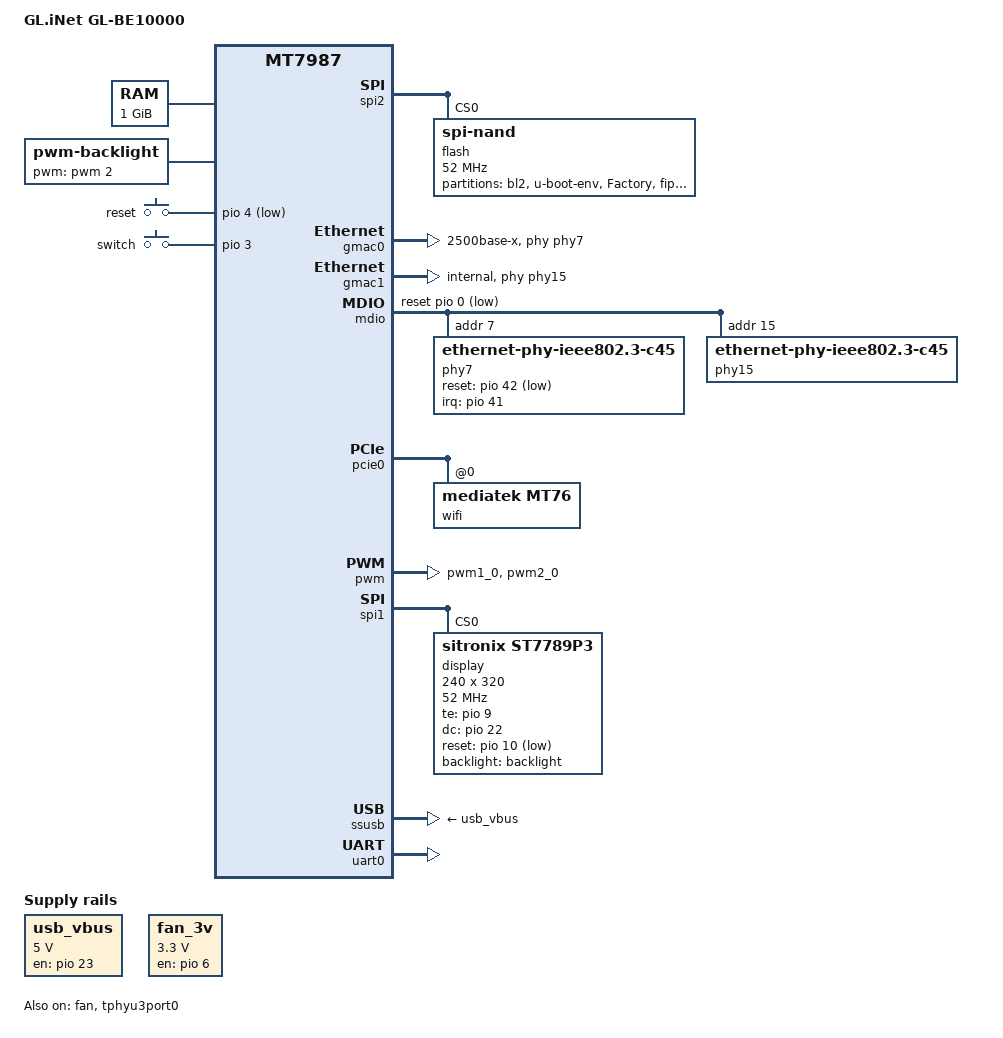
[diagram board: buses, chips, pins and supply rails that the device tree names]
// SPDX-License-Identifier: GPL-2.0-or-later OR MIT
/dts-v1/;
#include "mt7987a.dtsi"
#include <dt-bindings/input/input.h>

/ {
	model = "GL.iNet GL-BE10000";
	compatible = "glinet,gl-be10000", "mediatek,mt7987a", "mediatek,mt7987";

	memory@40000000 {
		device_type = "memory";
		reg = <0 0x40000000 0 0x40000000>;
	};

	aliases {
		serial0 = &uart0;
		label-mac-device = &gmac0;
	};

	backlight: backlight {
		compatible = "pwm-backlight";
		pwms = <&pwm 2 50000>;
		brightness-levels = <0    1    1    1    2    2    3    4    5    6    7
			  8    9   10   12   13   15   16   18   20   22
			 24   26   29   31   34   37   40   43   46   50
			 53   57   61   65   69   74   78   83   88   93
			 98  103  109  114  120  126  132  138  145  151
			158  165  172  179  187  194  202  210  218  226
			235  243  252  261  270  279  289  298  308  318
			328  338  349  359  370  381  392  403  415  426
			438  450  462  474  487  499  512  525  538  551
			565  578  592  606  620  634  649  663  678  693
			708  723  738  754  770  785  801  818  834  850
			867  884  901  918  935  952  970  988 1006 1023>;
		default-brightness-level = <95>;
	};

	chosen {
		bootargs = "console=ttyS0,115200n1 \
			    earlycon=uart8250,mmio32,0x11000000 \
			    pci=pcie_bus_perf \
			    fbcon=logo-count:1 vt.global_cursor_default=0";
		stdout-path = "serial0:115200n8";
	};

	gpio-keys {
		compatible = "gpio-keys";

		reset {
			label = "reset";
			linux,code = <KEY_RESTART>;
			gpios = <&pio 4 GPIO_ACTIVE_LOW>;
			debounce-interval = <10>;
		};

		switch {
			label = "switch";
			linux,code = <BTN_0>;
			gpios = <&pio 3 GPIO_ACTIVE_HIGH>;
			debounce-interval = <10>;
		};
	};

	usb_vbus: regulator-usb-vbus {
		compatible = "regulator-fixed";
		enable-active-high;
		gpios = <&pio 23 GPIO_ACTIVE_HIGH>;
		regulator-name = "usb_vbus";
		regulator-boot-on;
		regulator-min-microvolt = <5000000>;
		regulator-max-microvolt = <5000000>;
	};

	fan_3v: regulator-fan-3p3v {
		compatible = "regulator-fixed";
		enable-active-high;
		gpios = <&pio 6 GPIO_ACTIVE_HIGH>;
		regulator-name = "fan";
		regulator-min-microvolt = <3300000>;
		regulator-max-microvolt = <3300000>;
	};
};

&fan {
	fan-supply = <&fan_3v>;
	interrupt-parent = <&pio>;
	interrupts = <5 IRQ_TYPE_EDGE_RISING>;
	pwms = <&pwm 1 50000 0>;
	status = "okay";
};

&spi2 {
	pinctrl-names = "default";
	pinctrl-0 = <&spi2_flash_pins>;
	status = "okay";

	flash@0 {
		compatible = "spi-nand";
		reg = <0>;
		spi-max-frequency = <52000000>;
		spi-rx-bus-width = <4>;
		spi-tx-bus-width = <4>;
		mediatek,nmbm;
		mediatek,bmt-max-ratio = <1>;
		mediatek,bmt-max-reserved-blocks = <64>;

		partitions {
			compatible = "fixed-partitions";
			#address-cells = <1>;
			#size-cells = <1>;

			partition@0 {
				label = "bl2";
				reg = <0x00000 0x0100000>;
				read-only;
			};

			partition@100000 {
				label = "u-boot-env";
				reg = <0x0100000 0x0080000>;
			};

			factory: partition@180000 {
				label = "Factory";
				reg = <0x180000 0x0400000>;

				nvmem-layout {
					compatible = "fixed-layout";
					#address-cells = <1>;
					#size-cells = <1>;

					eeprom_factory_0: eeprom@0 {
						reg = <0x0 0x1e00>;
					};

					macaddr_factory_4: macaddr@4000 {
						reg = <0x4000 0x6>;
						compatible = "mac-base";
						#nvmem-cell-cells = <1>;
					};
				};
			};

			partition@580000 {
				label = "fip";
				reg = <0x580000 0x0300000>;
			};

			partition@880000 {
				label = "log";
				reg = <0x880000 0x0040000>;
			};

			partition@8c0000 {
				label = "CFG";
				reg = <0x8c0000 0x0040000>;
			};

			partition@900000 {
				label = "ubi";
				reg = <0x900000 0x1d700000>;
				compatible = "linux,ubi";
			};
		};
	};
};

&gmac0 {
	phy-mode = "2500base-x";
	phy-handle = <&phy7>;
	status = "okay";
	nvmem-cells = <&macaddr_factory_4 0>;
	nvmem-cell-names = "mac-address";
};

&gmac1 {
	phy-mode = "internal";
	phy-handle = <&phy15>;
	status = "okay";
	nvmem-cells = <&macaddr_factory_4 1>;
	nvmem-cell-names = "mac-address";
};

&mdio {
	reset-gpios = <&pio 0 GPIO_ACTIVE_LOW>;
	reset-delay-us = <10000>;

	phy7: phy@7 {
		compatible = "ethernet-phy-ieee802.3-c45";
		reg = <7>;
		reset-assert-us = <100000>;
		reset-deassert-us = <100000>;
		reset-gpios = <&pio 42 GPIO_ACTIVE_LOW>;
		interrupt-parent = <&pio>;
		interrupts = <41 IRQ_TYPE_LEVEL_LOW>;
	};

	phy15: phy@f {
		compatible = "ethernet-phy-ieee802.3-c45";
		reg = <15>;
		pinctrl-names = "i2p5gbe-led";
		pinctrl-0 = <&i2p5gbe_led0_pins>;
	};
};

&pcie0 {
	pinctrl-names = "default";
	pinctrl-0 = <&pcie0_pins>;
	status = "okay";

	pcie@0,0 {
		reg = <0x0000 0 0 0 0>;
		#address-cells = <3>;
		#size-cells = <2>;

		wifi@0,0 {
			compatible = "mediatek,mt76";
			reg = <0x0000 0 0 0 0>;

			nvmem-cells = <&eeprom_factory_0>;
			nvmem-cell-names = "eeprom";

			#address-cells = <1>;
			#size-cells = <0>;

			ieee80211-freq-limit = <2400000 2500000>,
					       <5170000 5835000>,
					       <5945000 7125000>;

			band@0 {
				reg = <0>;
				nvmem-cells = <&macaddr_factory_4 2>;
				nvmem-cell-names = "mac-address";
			};

			band@1 {
				reg = <1>;
				nvmem-cells = <&macaddr_factory_4 3>;
				nvmem-cell-names = "mac-address";
			};

			band@2 {
				reg = <2>;
				nvmem-cells = <&macaddr_factory_4 4>;
				nvmem-cell-names = "mac-address";
			};
		};
	};
};

&pio {
	pwm1_pins: pwm1-pins {
		mux {
			function = "pwm";
			groups = "pwm1_0";
		};
	};

	pwm2_pins: pwm2-pins {
		mux {
			function = "pwm";
			groups = "pwm2_0";
		};
	};
};

&pwm {
	pinctrl-names = "default";
	pinctrl-0 = <&pwm1_pins &pwm2_pins>;
	status = "okay";
};

&spi1 {
	pinctrl-names = "default";
	pinctrl-0 = <&spic_pins>;
	cs_setup_time = <2>;
	status = "okay";

	display@0 {
		compatible = "sitronix,st7789p3";
		reg = <0>;
		backlight = <&backlight>;
		buswidth = <8>;
		width = <240>;
		height = <320>;
		rotate = <0>;
		fps = <40>;
		te-gpios = <&pio 9 GPIO_ACTIVE_HIGH>;
		dc-gpios = <&pio 22 GPIO_ACTIVE_HIGH>;
		reset-gpios = <&pio 10 GPIO_ACTIVE_LOW>;
		spi-max-frequency = <52000000>;
	};
};

&spic_pins {
	mux {
		function = "spi";
		groups = "spi1_1";
	};
};

&ssusb {
	vbus-supply = <&usb_vbus>;
	status = "okay";
};

&tphyu3port0 {
	status = "okay";
};

&uart0 {
	pinctrl-names = "default";
	pinctrl-0 = <&uart0_pins>;
	status = "okay";
};
